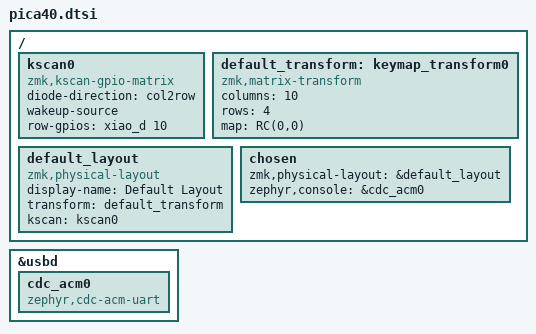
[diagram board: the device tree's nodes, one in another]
#include <dt-bindings/zmk/matrix_transform.h>
#include <physical_layouts.dtsi>

/ {
    kscan0: kscan0 {
        compatible = "zmk,kscan-gpio-matrix";
        diode-direction = "col2row";
        wakeup-source;

        row-gpios
            = <&xiao_d 10 (GPIO_ACTIVE_HIGH | GPIO_PULL_DOWN)>
            ;
    };
};

/ {
    default_transform: keymap_transform0 {
        compatible = "zmk,matrix-transform";
        columns = <10>;
        rows = <4>;
        map = <
                    RC(0,0) 
        >;
    };
};

/ {
    default_layout: default_layout {
        compatible = "zmk,physical-layout";
        display-name = "Default Layout";
        transform = <&default_transform>;
        kscan = <&kscan0>;
    };
};
&usbd {
    cdc_acm0: cdc_acm0 {
        compatible = "zephyr,cdc-acm-uart";
    };
};

/ {
    chosen {
        zmk,physical-layout = &default_layout;
        zephyr,console = &cdc_acm0;
    };
};
